AUTOSAR XML (schema 314)
package /ComponentType
  internal behavior Sa_MtrPosSnsrLearning_InternalBehavior: component=Sa_MtrPosSnsrLearning
    timing event MtrPosSnsrLearning_Init1_InitEvent: start-on-event=MtrPosSnsrLearning_Init1, period=0
    timing event TMT_MtrPosSnsrLearning_Per1: mode-dependency=dependent-on-mode=SystemState.Mode.OFF, start-on-event=MtrPosSnsrLearning_Per1, period=0.002
    mode switch event MST_MtrPosSnsrLearning_Trns1_0: start-on-event=MtrPosSnsrLearning_Trns1, activation=ENTRY, mode=SystemState.Mode.OFF
    18 x inter runnable variable, all with sw-calibration-access=READ-ONLY, communication-approach=EXPLICIT:
      Cos1GainCorr_Uls_f32: type=Float, init-value=D_FLOATZERO_ULS_F32
      Cos1MaxSV_Volts_s2p29: type=SInt32, init-value=D_SIGNED32ZERO_CNT_S32
      Cos1MinSV_Volts_s2p29: type=SInt32, init-value=D_SIGNED32ZERO_CNT_S32
      Cos1OffsetCorr_Volts_f32: type=Float, init-value=D_FLOATZERO_ULS_F32
      Cos2MaxSV_Volts_s2p29: type=SInt32, init-value=D_SIGNED32ZERO_CNT_S32
      Cos2MinSV_Volts_s2p29: type=SInt32, init-value=D_SIGNED32ZERO_CNT_S32
      CosSin1NomRatio_Uls_f32: type=Float, init-value=D_FLOATZERO_ULS_F32
      CosSin2NomRatio_Uls_f32: type=Float, init-value=D_FLOATZERO_ULS_F32
      RTToNomHighLmt_Uls_f32: type=Float, init-value=D_FLOATZERO_ULS_F32
      RTToNomLowLmt_Uls_f32: type=Float, init-value=D_FLOATZERO_ULS_F32
      Sin1GainCorr_Uls_f32: type=Float, init-value=D_FLOATZERO_ULS_F32
      Sin1MaxSV_Volts_s2p29: type=SInt32, init-value=D_SIGNED32ZERO_CNT_S32
      Sin1MinSV_Volts_s2p29: type=SInt32, init-value=D_SIGNED32ZERO_CNT_S32
      Sin1OffsetCorr_Volts_f32: type=Float, init-value=D_FLOATZERO_ULS_F32
      Sin2MaxSV_Volts_s2p29: type=SInt32, init-value=D_SIGNED32ZERO_CNT_S32
      Sin2MinSV_Volts_s2p29: type=SInt32, init-value=D_SIGNED32ZERO_CNT_S32
      SinCos1NomRatio_Uls_f32: type=Float, init-value=D_FLOATZERO_ULS_F32
      SinCos2NomRatio_Uls_f32: type=Float, init-value=D_FLOATZERO_ULS_F32
    per instance memory MtrSnsrLearnedParam: type=MtrSnsrLearned_DataType, type-definition=/DataType/MtrSnsrLearned_DataType
    port-api-options:
      enable-take-address=false, indirect-api=false, port=Cos1RTAmpRec
      enable-take-address=false, indirect-api=false, port=Cos1RTOffset
      enable-take-address=false, indirect-api=false, port=Cos1Theta
      enable-take-address=false, indirect-api=false, port=Cos2RTAmpRec
      enable-take-address=false, indirect-api=false, port=Cos2RTOffset
      enable-take-address=false, indirect-api=false, port=EOLMtrSnsrAdjParam
      enable-take-address=false, indirect-api=false, port=LearnedMtrSnsrParam
      enable-take-address=false, indirect-api=false, port=MRFMtrVel
      enable-take-address=false, indirect-api=false, port=MtrPos
      enable-take-address=false, indirect-api=false, port=MtrPosMech
      enable-take-address=false, indirect-api=false, port=MtrPosMech2
      enable-take-address=false, indirect-api=false, port=NxtrDiagMgr
      enable-take-address=false, indirect-api=false, port=Sin1RTAmpRec
      enable-take-address=false, indirect-api=false, port=Sin1RTOffset
      enable-take-address=false, indirect-api=false, port=Sin1Theta
      enable-take-address=false, indirect-api=false, port=Sin2RTAmpRec
      enable-take-address=false, indirect-api=false, port=Sin2RTOffset
      enable-take-address=false, indirect-api=false, port=SystemState
    runnable MtrPosSnsrLearning_Init1: written-variable=[Cos1GainCorr_Uls_f32, Cos1MaxSV_Volts_s2p29, Cos1MinSV_Volts_s2p29, Cos1OffsetCorr_Volts_f32, Cos2MaxSV_Volts_s2p29, Cos2MinSV_Volts_s2p29, CosSin1NomRatio_Uls_f32, CosSin2NomRatio_Uls_f32, RTToNomHighLmt_Uls_f32, RTToNomLowLmt_Uls_f32, Sin1GainCorr_Uls_f32, Sin1MaxSV_Volts_s2p29, Sin1MinSV_Volts_s2p29, Sin1OffsetCorr_Volts_f32, Sin2MaxSV_Volts_s2p29, Sin2MinSV_Volts_s2p29, SinCos1NomRatio_Uls_f32, SinCos2NomRatio_Uls_f32]
      12 x data read access:
        READ_EOLMtrSnsrAdjParam_EOLCos1AmpRec_Uls_f32: data-element=EOLMtrSnsrAdjParam.EOLCos1AmpRec_Uls_f32
        READ_EOLMtrSnsrAdjParam_EOLCos1GainCorr_Uls_f32: data-element=EOLMtrSnsrAdjParam.EOLCos1GainCorr_Uls_f32
        READ_EOLMtrSnsrAdjParam_EOLCos1Offset_Volts_f32: data-element=EOLMtrSnsrAdjParam.EOLCos1Offset_Volts_f32
        READ_EOLMtrSnsrAdjParam_EOLCos1OffsetCorr_Volts_f32: data-element=EOLMtrSnsrAdjParam.EOLCos1OffsetCorr_Volts_f32
        READ_EOLMtrSnsrAdjParam_EOLCos2AmpRec_Uls_f32: data-element=EOLMtrSnsrAdjParam.EOLCos2AmpRec_Uls_f32
        READ_EOLMtrSnsrAdjParam_EOLCos2Offset_Volts_f32: data-element=EOLMtrSnsrAdjParam.EOLCos2Offset_Volts_f32
        READ_EOLMtrSnsrAdjParam_EOLSin1AmpRec_Uls_f32: data-element=EOLMtrSnsrAdjParam.EOLSin1AmpRec_Uls_f32
        READ_EOLMtrSnsrAdjParam_EOLSin1GainCorr_Uls_f32: data-element=EOLMtrSnsrAdjParam.EOLSin1GainCorr_Uls_f32
        READ_EOLMtrSnsrAdjParam_EOLSin1Offset_Volts_f32: data-element=EOLMtrSnsrAdjParam.EOLSin1Offset_Volts_f32
        READ_EOLMtrSnsrAdjParam_EOLSin1OffsetCorr_Volts_f32: data-element=EOLMtrSnsrAdjParam.EOLSin1OffsetCorr_Volts_f32
        READ_EOLMtrSnsrAdjParam_EOLSin2AmpRec_Uls_f32: data-element=EOLMtrSnsrAdjParam.EOLSin2AmpRec_Uls_f32
        READ_EOLMtrSnsrAdjParam_EOLSin2Offset_Volts_f32: data-element=EOLMtrSnsrAdjParam.EOLSin2Offset_Volts_f32
      8 x data send point:
        SEND_Cos1RTAmpRec_Uls_f32: data-element=Cos1RTAmpRec.Uls_f32
        SEND_Cos1RTOffset_Volts_f32: data-element=Cos1RTOffset.Volts_f32
        SEND_Cos2RTAmpRec_Uls_f32: data-element=Cos2RTAmpRec.Uls_f32
        SEND_Cos2RTOffset_Volts_f32: data-element=Cos2RTOffset.Volts_f32
        SEND_Sin1RTAmpRec_Uls_f32: data-element=Sin1RTAmpRec.Uls_f32
        SEND_Sin1RTOffset_Volts_f32: data-element=Sin1RTOffset.Volts_f32
        SEND_Sin2RTAmpRec_Uls_f32: data-element=Sin2RTAmpRec.Uls_f32
        SEND_Sin2RTOffset_Volts_f32: data-element=Sin2RTOffset.Volts_f32
    runnable MtrPosSnsrLearning_Per1: read-variable=[Cos1GainCorr_Uls_f32, Cos1MaxSV_Volts_s2p29, Cos1MinSV_Volts_s2p29, Cos1OffsetCorr_Volts_f32, Cos2MaxSV_Volts_s2p29, Cos2MinSV_Volts_s2p29, CosSin1NomRatio_Uls_f32, CosSin2NomRatio_Uls_f32, RTToNomHighLmt_Uls_f32, RTToNomLowLmt_Uls_f32, Sin1GainCorr_Uls_f32, Sin1MaxSV_Volts_s2p29, Sin1MinSV_Volts_s2p29, Sin1OffsetCorr_Volts_f32, Sin2MaxSV_Volts_s2p29, Sin2MinSV_Volts_s2p29, SinCos1NomRatio_Uls_f32, SinCos2NomRatio_Uls_f32], written-variable=[Cos1MaxSV_Volts_s2p29, Cos1MinSV_Volts_s2p29, Cos2MaxSV_Volts_s2p29, Cos2MinSV_Volts_s2p29, Sin1MaxSV_Volts_s2p29, Sin1MinSV_Volts_s2p29, Sin2MaxSV_Volts_s2p29, Sin2MinSV_Volts_s2p29]
      11 x data read access:
        READ_Cos1Theta_Volts_f32: data-element=Cos1Theta.Volts_f32
        READ_EOLMtrSnsrAdjParam_EOLCos1Offset_Volts_f32: data-element=EOLMtrSnsrAdjParam.EOLCos1Offset_Volts_f32
        READ_EOLMtrSnsrAdjParam_EOLCos2Offset_Volts_f32: data-element=EOLMtrSnsrAdjParam.EOLCos2Offset_Volts_f32
        READ_EOLMtrSnsrAdjParam_EOLSin1AmpRec_Uls_f32: data-element=EOLMtrSnsrAdjParam.EOLSin1AmpRec_Uls_f32
        READ_EOLMtrSnsrAdjParam_EOLSin1Offset_Volts_f32: data-element=EOLMtrSnsrAdjParam.EOLSin1Offset_Volts_f32
        READ_EOLMtrSnsrAdjParam_EOLSin2AmpRec_Uls_f32: data-element=EOLMtrSnsrAdjParam.EOLSin2AmpRec_Uls_f32
        READ_EOLMtrSnsrAdjParam_EOLSin2Offset_Volts_f32: data-element=EOLMtrSnsrAdjParam.EOLSin2Offset_Volts_f32
        READ_MRFMtrVel_MtrRadpS_f32: data-element=MRFMtrVel.MtrRadpS_f32
        READ_MtrPosMech_Rev_f32: data-element=MtrPosMech.Rev_f32
        READ_MtrPosMech2_Rev_f32: data-element=MtrPosMech2.Rev_f32
        READ_Sin1Theta_Volts_f32: data-element=Sin1Theta.Volts_f32
      8 x data send point:
        SEND_Cos1RTAmpRec_Uls_f32: data-element=Cos1RTAmpRec.Uls_f32
        SEND_Cos1RTOffset_Volts_f32: data-element=Cos1RTOffset.Volts_f32
        SEND_Cos2RTAmpRec_Uls_f32: data-element=Cos2RTAmpRec.Uls_f32
        SEND_Cos2RTOffset_Volts_f32: data-element=Cos2RTOffset.Volts_f32
        SEND_Sin1RTAmpRec_Uls_f32: data-element=Sin1RTAmpRec.Uls_f32
        SEND_Sin1RTOffset_Volts_f32: data-element=Sin1RTOffset.Volts_f32
        SEND_Sin2RTAmpRec_Uls_f32: data-element=Sin2RTAmpRec.Uls_f32
        SEND_Sin2RTOffset_Volts_f32: data-element=Sin2RTOffset.Volts_f32
      sync call SC_MtrPos_InvCosTheta2_V_f32: operation=MtrPos.InvCosTheta2_V_f32, timeout=0
      sync call SC_MtrPos_InvSinTheta2_V_f32: operation=MtrPos.InvSinTheta2_V_f32, timeout=0
      sync call SC_NxtrDiagMgr_GetNTCFailed: operation=NxtrDiagMgr.GetNTCFailed, timeout=0
    runnable MtrPosSnsrLearning_Trns1
      sync call SC_LearnedMtrSnsrParam_SetRamBlockStatus: operation=LearnedMtrSnsrParam.SetRamBlockStatus, timeout=0
    service-needss:
      swc nv block needs MtrSnsrLrnParam: n-data-sets=0, readonly=false, reliability=LOW, resistant-to-changed-sw=false, restore-at-start=false, write-only-once=false, writing-frequency=0, writing-priority=LOW, mirror-block=MtrSnsrLearnedParam
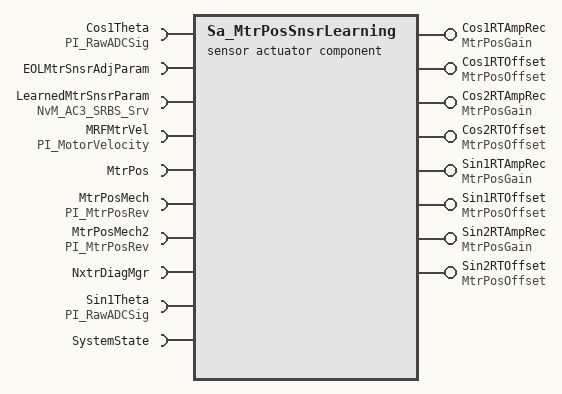
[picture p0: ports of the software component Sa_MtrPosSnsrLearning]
  sensor actuator software component type Sa_MtrPosSnsrLearning
    8 x provide port:
      Cos1RTAmpRec: unqueued-sender-com-spec{data-element=Uls_f32, can-invalidate=false, init-value=D_FLOATZERO_ULS_F32}, provided-interface=MtrPosGain
      Cos1RTOffset: unqueued-sender-com-spec{data-element=Volts_f32, can-invalidate=false, init-value=D_FLOATZERO_ULS_F32}, provided-interface=MtrPosOffset
      Cos2RTAmpRec: unqueued-sender-com-spec{data-element=Uls_f32, can-invalidate=false, init-value=D_FLOATZERO_ULS_F32}, provided-interface=MtrPosGain
      Cos2RTOffset: unqueued-sender-com-spec{data-element=Volts_f32, can-invalidate=false, init-value=D_FLOATZERO_ULS_F32}, provided-interface=MtrPosOffset
      Sin1RTAmpRec: unqueued-sender-com-spec{data-element=Uls_f32, can-invalidate=false, init-value=D_FLOATZERO_ULS_F32}, provided-interface=MtrPosGain
      Sin1RTOffset: unqueued-sender-com-spec{data-element=Volts_f32, can-invalidate=false, init-value=D_FLOATZERO_ULS_F32}, provided-interface=MtrPosOffset
      Sin2RTAmpRec: unqueued-sender-com-spec{data-element=Uls_f32, can-invalidate=false, init-value=D_FLOATZERO_ULS_F32}, provided-interface=MtrPosGain
      Sin2RTOffset: unqueued-sender-com-spec{data-element=Volts_f32, can-invalidate=false, init-value=D_FLOATZERO_ULS_F32}, provided-interface=MtrPosOffset
    10 x require port:
      Cos1Theta: unqueued-receiver-com-spec{data-element=Volts_f32, init-value=D_FLOATZERO_ULS_F32}, required-interface=PI_RawADCSig
      EOLMtrSnsrAdjParam: required-interface=EOLMtrSnsrAdjParam
        required-com-specs:
          data-element=EOLCos1AmpRec_Uls_f32, init-value=D_FLOATZERO_ULS_F32
          data-element=EOLCos1GainCorr_Uls_f32, init-value=D_FLOATZERO_ULS_F32
          data-element=EOLCos1Offset_Volts_f32, init-value=D_FLOATZERO_ULS_F32
          data-element=EOLCos1OffsetCorr_Volts_f32, init-value=D_FLOATZERO_ULS_F32
          data-element=EOLCos2AmpRec_Uls_f32, init-value=D_FLOATZERO_ULS_F32
          data-element=EOLCos2Offset_Volts_f32, init-value=D_FLOATZERO_ULS_F32
          data-element=EOLSin1AmpRec_Uls_f32, init-value=D_FLOATZERO_ULS_F32
          data-element=EOLSin1GainCorr_Uls_f32, init-value=D_FLOATZERO_ULS_F32
          data-element=EOLSin1Offset_Volts_f32, init-value=D_FLOATZERO_ULS_F32
          data-element=EOLSin1OffsetCorr_Volts_f32, init-value=D_FLOATZERO_ULS_F32
          data-element=EOLSin2AmpRec_Uls_f32, init-value=D_FLOATZERO_ULS_F32
          data-element=EOLSin2Offset_Volts_f32, init-value=D_FLOATZERO_ULS_F32
      LearnedMtrSnsrParam: required-com-specs=[EraseBlock, GetErrorStatus, InvalidateNvBlock, ReadBlock, SetRamBlockStatus, WriteBlock], required-interface=NvM_AC3_SRBS_Srv
      MRFMtrVel: unqueued-receiver-com-spec{data-element=MtrRadpS_f32, init-value=D_FLOATZERO_ULS_F32}, required-interface=PI_MotorVelocity
      MtrPos: required-com-specs=[CosTheta1_V_f32, InvCosTheta2_V_f32, InvSinTheta2_V_f32, SinTheta1_V_f32], required-interface=MtrPos
      MtrPosMech: unqueued-receiver-com-spec{data-element=Rev_f32, init-value=D_FLOATZERO_ULS_F32}, required-interface=PI_MtrPosRev
      MtrPosMech2: unqueued-receiver-com-spec{data-element=Rev_f32, init-value=D_FLOATZERO_ULS_F32}, required-interface=PI_MtrPosRev
      NxtrDiagMgr: required-com-specs=[GetNTCFailed, GetNTCStatus, ResetEventStatus, SetNTCStatus, SetOperationCycleState], required-interface=NxtrDiagMgr
      Sin1Theta: unqueued-receiver-com-spec{data-element=Volts_f32, init-value=D_FLOATZERO_ULS_F32}, required-interface=PI_RawADCSig
      SystemState: required-interface=SystemState
  swc implementation Sa_MtrPosSnsrLearning_Implementation: behavior=Sa_MtrPosSnsrLearning_InternalBehavior
    code-descriptors:
      code Code: type=SRC
